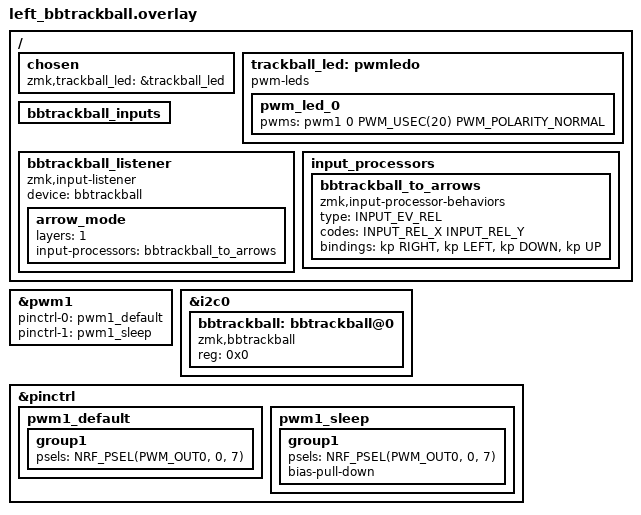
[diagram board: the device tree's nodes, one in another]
/*
*
* Copyright (c) 2025 ZitaoTech
* SPDX-License-Identifier: MIT
*
*/
#include <zephyr/dt-bindings/input/input-event-codes.h>
#include <dt-bindings/zmk/keys.h>

/ {
    chosen {
        zmk,trackball_led = &trackball_led;
    };
    trackball_led: pwmledo{
        compatible = "pwm-leds";
        pwm_led_0 {
            pwms = <&pwm1 0 PWM_USEC(20) PWM_POLARITY_NORMAL>;
        };
    };

};

&pwm1 {
    status = "okay";
    pinctrl-0 = <&pwm1_default>;
    pinctrl-1 = <&pwm1_sleep>;
    pinctrl-names = "default", "sleep";
};

&i2c0 {
    bbtrackball: bbtrackball@0 {
        compatible = "zmk,bbtrackball";
        reg = <0x0>;
        status = "okay";
    };
};

/ {
    bbtrackball_inputs {
        #address-cells = <1>;
        #size-cells = <0>;

    };
    bbtrackball_listener: bbtrackball_listener {
        compatible = "zmk,input-listener";
        status = "disabled";
        device = <&bbtrackball>;
    };

    /* 轨迹球→方向键转换器（黑莓模式） */
    input_processors {
        bbtrackball_to_arrows: bbtrackball_to_arrows {
            compatible = "zmk,input-processor-behaviors";
            #input-processor-cells = <0>;
            type = <INPUT_EV_REL>;
            codes = <INPUT_REL_X INPUT_REL_Y>;
            /* X轴：右→RIGHT，左→LEFT */
            /* Y轴：下→DOWN，上→UP */
            bindings = <&kp RIGHT &kp LEFT>,
                       <&kp DOWN &kp UP>;
        };
    };
};

&bbtrackball_listener {
    status = "okay";
    /* 默认：鼠标移动模式（不添加input-processors） */

    /* 在FUNC层（层1）启用方向键模式 */
    arrow_mode {
        layers = <1>;
        input-processors = <&bbtrackball_to_arrows>;
    };
};

&pinctrl {
    pwm1_default:pwm1_default{
        group1{
            psels = <NRF_PSEL(PWM_OUT0, 0, 7)>; // Backlight for Trackball
        };
    };

    pwm1_sleep: pwm1_sleep {
        group1 {
            psels = <NRF_PSEL(PWM_OUT0, 0, 7)>;
            bias-pull-down;
        };
    };
};

